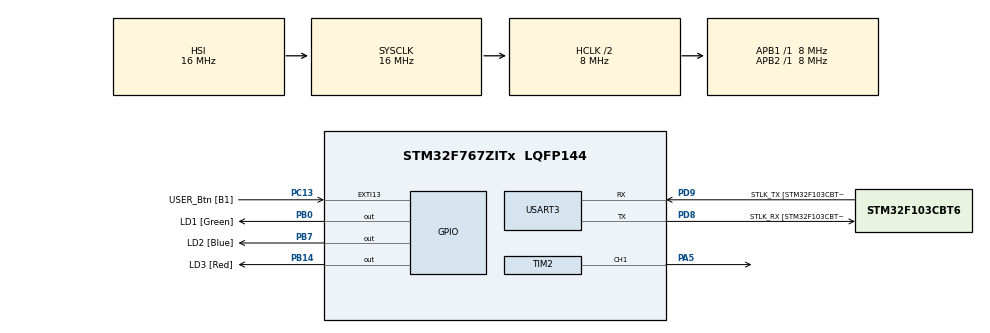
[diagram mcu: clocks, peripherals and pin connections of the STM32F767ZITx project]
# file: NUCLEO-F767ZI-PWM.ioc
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Mcu.Family=STM32F7
Mcu.Name=STM32F767ZITx
Mcu.Package=LQFP144
NVIC.PriorityGroup=NVIC_PRIORITYGROUP_4
PA13.GPIO_Label=TMS
PA13.Mode=Serial_Wire
PA13.Signal=SYS_JTMS-SWDIO
PA14.GPIO_Label=TCK
PA14.Mode=Serial_Wire
PA14.Signal=SYS_JTCK-SWCLK
PA5.Signal=S_TIM2_CH1_ETR
PB0.GPIO_Label=LD1 [Green]
PB0.Signal=GPIO_Output
PB14.GPIO_Label=LD3 [Red]
PB14.Signal=GPIO_Output
PB3.GPIO_Label=SWO
PB3.Signal=SYS_JTDO-SWO
PB7.GPIO_Label=LD2 [Blue]
PB7.Signal=GPIO_Output
PC13.GPIO_Label=USER_Btn [B1]
PC13.Signal=GPXTI13
PC14/OSC32_IN.Mode=LSE-External-Oscillator
PC14/OSC32_IN.Signal=RCC_OSC32_IN
PC15/OSC32_OUT.Mode=LSE-External-Oscillator
PC15/OSC32_OUT.Signal=RCC_OSC32_OUT
PD8.GPIO_Label=STLK_RX [STM32F103CBT6_PA3]
PD8.Mode=Asynchronous
PD8.Signal=USART3_TX
PD9.GPIO_Label=STLK_TX [STM32F103CBT6_PA2]
PD9.Mode=Asynchronous
PD9.Signal=USART3_RX
PH0/OSC_IN.GPIO_Label=MCO [STM32F103CBT6_PA8]
PH0/OSC_IN.Mode=HSE-External-Clock-Source
PH0/OSC_IN.Signal=RCC_OSC_IN
PH1/OSC_OUT.Mode=HSE-External-Clock-Source
PH1/OSC_OUT.Signal=RCC_OSC_OUT
ProjectManager.HeapSize=0x200
ProjectManager.StackSize=0x400
ProjectManager.TargetToolchain=STM32CubeIDE
RCC.48MHZClocksFreq_Value=24000000
RCC.AHBCLKDivider=RCC_SYSCLK_DIV2
RCC.AHBFreq_Value=8000000
RCC.APB1Freq_Value=8000000
RCC.APB1TimFreq_Value=8000000
RCC.APB2Freq_Value=8000000
RCC.APB2TimFreq_Value=8000000
RCC.CortexFreq_Value=8000000
RCC.HCLKFreq_Value=8000000
RCC.HSE_VALUE=8000000
RCC.HSI_VALUE=16000000
RCC.PLLM=4
RCC.PLLMUL=RCC_PLL_MUL9
RCC.PLLN=96
RCC.PLLQ=4
RCC.PLLSourceVirtual=RCC_PLLSOURCE_HSE
RCC.PRESCALERUSB=RCC_USBCLKSOURCE_PLL_DIV1_5
RCC.SYSCLKFreq_VALUE=16000000
RCC.SYSCLKSourceVirtual=RCC_SYSCLKSOURCE_PLLCLK
RCC.USBFreq_Value=48000000
RCC.VCOOutputFreq_Value=192000000
SH.S_TIM2_CH1_ETR.0=TIM2_CH1,PWM Generation1 CH1
TIM2.Channel-PWM\ Generation1\ CH1=TIM_CHANNEL_1
TIM2.Period=62499
TIM2.Prescaler=127
TIM2.Pulse-PWM\ Generation1\ CH1=31250
USART3.VirtualMode-Asynchronous=VM_ASYNC
VP_TIM2_VS_ClockSourceINT.Mode=Internal
board=NUCLEO-F767ZI

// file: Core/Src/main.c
/* USER CODE BEGIN Header */
/**
  ******************************************************************************
  * @file           : main.c
  * @brief          : Main program body
  ******************************************************************************
  * @attention
  *
  * Copyright (c) 2022 STMicroelectronics.
  * All rights reserved.
  *
  * This software is licensed under terms that can be found in the LICENSE file
  * in the root directory of this software component.
  * If no LICENSE file comes with this software, it is provided AS-IS.
  *
  ******************************************************************************
  */
/* USER CODE END Header */
#include "main.h"

TIM_HandleTypeDef htim2;

UART_HandleTypeDef huart3;

void SystemClock_Config(void);
static void MX_GPIO_Init(void);
static void MX_USART3_UART_Init(void);
static void MX_TIM2_Init(void);

int main(void)
{

  /* MCU Configuration--------------------------------------------------------*/

  /* Reset of all peripherals, Initializes the Flash interface and the Systick. */
  HAL_Init();

  /* Configure the system clock */
  SystemClock_Config();

  /* Initialize all configured peripherals */
  MX_GPIO_Init();
  MX_USART3_UART_Init();
  MX_TIM2_Init();
  /* USER CODE BEGIN 2 */
  if ( HAL_TIM_PWM_Start( &htim2, TIM_CHANNEL_1 ) != HAL_OK )
  {
	  Error_Handler();
  }

  /* USER CODE END 2 */

  /* Infinite loop */
  while (1)
  {

  }
}

void SystemClock_Config(void)
{
  RCC_OscInitTypeDef RCC_OscInitStruct = {0};
  RCC_ClkInitTypeDef RCC_ClkInitStruct = {0};

  /** Configure LSE Drive Capability
  */
  HAL_PWR_EnableBkUpAccess();
  /** Configure the main internal regulator output voltage
  */
  __HAL_RCC_PWR_CLK_ENABLE();
  __HAL_PWR_VOLTAGESCALING_CONFIG(PWR_REGULATOR_VOLTAGE_SCALE3);
  /** Initializes the RCC Oscillators according to the specified parameters
  * in the RCC_OscInitTypeDef structure.
  */
  RCC_OscInitStruct.OscillatorType = RCC_OSCILLATORTYPE_HSI;
  RCC_OscInitStruct.HSIState = RCC_HSI_ON;
  RCC_OscInitStruct.HSICalibrationValue = RCC_HSICALIBRATION_DEFAULT;
  RCC_OscInitStruct.PLL.PLLState = RCC_PLL_NONE;
  if (HAL_RCC_OscConfig(&RCC_OscInitStruct) != HAL_OK)
  {
    Error_Handler();
  }
  /** Initializes the CPU, AHB and APB buses clocks
  */
  RCC_ClkInitStruct.ClockType = RCC_CLOCKTYPE_HCLK|RCC_CLOCKTYPE_SYSCLK
                              |RCC_CLOCKTYPE_PCLK1|RCC_CLOCKTYPE_PCLK2;
  RCC_ClkInitStruct.SYSCLKSource = RCC_SYSCLKSOURCE_HSI;
  RCC_ClkInitStruct.AHBCLKDivider = RCC_SYSCLK_DIV2;
  RCC_ClkInitStruct.APB1CLKDivider = RCC_HCLK_DIV1;
  RCC_ClkInitStruct.APB2CLKDivider = RCC_HCLK_DIV1;

  if (HAL_RCC_ClockConfig(&RCC_ClkInitStruct, FLASH_LATENCY_0) != HAL_OK)
  {
    Error_Handler();
  }
}

static void MX_TIM2_Init(void)
{

  TIM_ClockConfigTypeDef sClockSourceConfig = {0};
  TIM_MasterConfigTypeDef sMasterConfig = {0};
  TIM_OC_InitTypeDef sConfigOC = {0};

  htim2.Instance = TIM2;
  htim2.Init.Prescaler = 127;
  htim2.Init.CounterMode = TIM_COUNTERMODE_UP;
  htim2.Init.Period = 62499;
  htim2.Init.ClockDivision = TIM_CLOCKDIVISION_DIV1;
  htim2.Init.AutoReloadPreload = TIM_AUTORELOAD_PRELOAD_DISABLE;
  if (HAL_TIM_Base_Init(&htim2) != HAL_OK)
  {
    Error_Handler();
  }
  sClockSourceConfig.ClockSource = TIM_CLOCKSOURCE_INTERNAL;
  if (HAL_TIM_ConfigClockSource(&htim2, &sClockSourceConfig) != HAL_OK)
  {
    Error_Handler();
  }
  if (HAL_TIM_PWM_Init(&htim2) != HAL_OK)
  {
    Error_Handler();
  }
  sMasterConfig.MasterOutputTrigger = TIM_TRGO_RESET;
  sMasterConfig.MasterSlaveMode = TIM_MASTERSLAVEMODE_DISABLE;
  if (HAL_TIMEx_MasterConfigSynchronization(&htim2, &sMasterConfig) != HAL_OK)
  {
    Error_Handler();
  }
  sConfigOC.OCMode = TIM_OCMODE_PWM1;
  sConfigOC.Pulse = 31250;
  sConfigOC.OCPolarity = TIM_OCPOLARITY_HIGH;
  sConfigOC.OCFastMode = TIM_OCFAST_DISABLE;
  if (HAL_TIM_PWM_ConfigChannel(&htim2, &sConfigOC, TIM_CHANNEL_1) != HAL_OK)
  {
    Error_Handler();
  }
  HAL_TIM_MspPostInit(&htim2);

}

static void MX_USART3_UART_Init(void)
{

  huart3.Instance = USART3;
  huart3.Init.BaudRate = 115200;
  huart3.Init.WordLength = UART_WORDLENGTH_8B;
  huart3.Init.StopBits = UART_STOPBITS_1;
  huart3.Init.Parity = UART_PARITY_NONE;
  huart3.Init.Mode = UART_MODE_TX_RX;
  huart3.Init.HwFlowCtl = UART_HWCONTROL_NONE;
  huart3.Init.OverSampling = UART_OVERSAMPLING_16;
  huart3.Init.OneBitSampling = UART_ONE_BIT_SAMPLE_DISABLE;
  huart3.AdvancedInit.AdvFeatureInit = UART_ADVFEATURE_NO_INIT;
  if (HAL_UART_Init(&huart3) != HAL_OK)
  {
    Error_Handler();
  }

}

static void MX_GPIO_Init(void)
{
  GPIO_InitTypeDef GPIO_InitStruct = {0};

  /* GPIO Ports Clock Enable */
  __HAL_RCC_GPIOC_CLK_ENABLE();
  __HAL_RCC_GPIOH_CLK_ENABLE();
  __HAL_RCC_GPIOA_CLK_ENABLE();
  __HAL_RCC_GPIOB_CLK_ENABLE();
  __HAL_RCC_GPIOD_CLK_ENABLE();

  /*Configure GPIO pin Output Level */
  HAL_GPIO_WritePin(GPIOB, LD1_Pin|LD3_Pin|LD2_Pin, GPIO_PIN_RESET);

  /*Configure GPIO pin : USER_Btn_Pin */
  GPIO_InitStruct.Pin = USER_Btn_Pin;
  GPIO_InitStruct.Mode = GPIO_MODE_IT_RISING;
  GPIO_InitStruct.Pull = GPIO_NOPULL;
  HAL_GPIO_Init(USER_Btn_GPIO_Port, &GPIO_InitStruct);

  /*Configure GPIO pins : LD1_Pin LD3_Pin LD2_Pin */
  GPIO_InitStruct.Pin = LD1_Pin|LD3_Pin|LD2_Pin;
  GPIO_InitStruct.Mode = GPIO_MODE_OUTPUT_PP;
  GPIO_InitStruct.Pull = GPIO_NOPULL;
  GPIO_InitStruct.Speed = GPIO_SPEED_FREQ_LOW;
  HAL_GPIO_Init(GPIOB, &GPIO_InitStruct);

}

void Error_Handler(void)
{
  __disable_irq();
  while (1)
  {
  }
}
